# M481_v1 register map
File version: 1.0
Registers are 32-bit, read-write, reset 0x0 unless marked. A register's access mark holds for its fields unless they carry their own. Offsets are from the block's base; [hi:lo] are bit positions; {n}, {i} and the like mark numbered series; 'fields as' and 'values as' point back to an identical list.

## CRYPTO — CRYPTO Register Map
Base 0x50080000
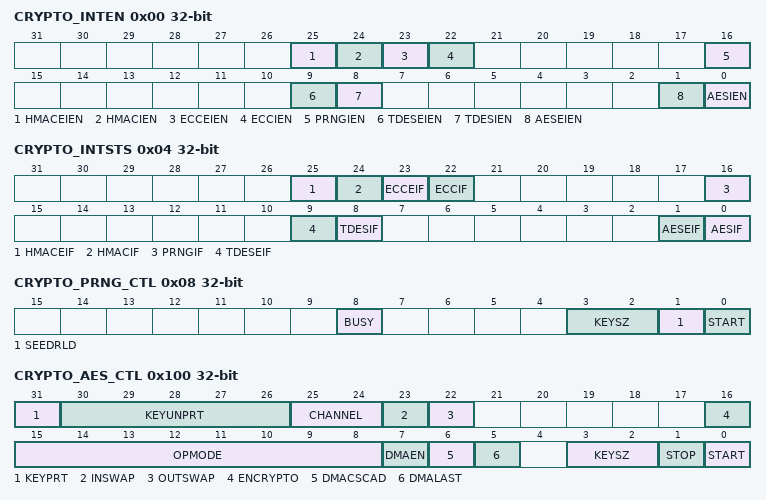
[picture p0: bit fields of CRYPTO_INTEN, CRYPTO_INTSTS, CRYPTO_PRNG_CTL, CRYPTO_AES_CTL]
0x00 CRYPTO_INTEN — Crypto Interrupt Enable Control Register
  [25] HMACEIEN — SHA/HMAC Error Interrupt Enable Bit
    0=SHA/HMAC error interrupt flag Disabled; 1=SHA/HMAC error interrupt flag Enabled
  [24] HMACIEN — SHA/HMAC Interrupt Enable Bit. Note: In DMA mode, an interrupt will be triggered when amount of data set in SHA _DMA_CNT is fed into the SHA/HMAC engine. In Non-DMA mode, an interrupt will be triggered when the SHA/HMAC engine finishes the operation.
    0=SHA/HMAC interrupt Disabled; 1=SHA/HMAC interrupt Enabled
  [23] ECCEIEN — ECC Error Interrupt Enable Bit
    0=ECC error interrupt flag Disabled; 1=ECC error interrupt flag Enabled
  [22] ECCIEN — ECC Interrupt Enable Bit. Note: In DMA mode, an interrupt will be triggered when amount of data set in ECC_DMA_CNT is fed into the ECC engine. In Non-DMA mode, an interrupt will be triggered when the ECC engine finishes the operation.
    0=ECC interrupt Disabled; 1=ECC interrupt Enabled
  [16] PRNGIEN — PRNG Interrupt Enable Bit
    0=PRNG interrupt Disabled; 1=PRNG interrupt Enabled
  [9] TDESEIEN — TDES/DES Error Flag Enable Bit
    0=TDES/DES error interrupt flag Disabled; 1=TDES/DES error interrupt flag Enabled
  [8] TDESIEN — TDES/DES Interrupt Enable Bit. Note: In DMA mode, an interrupt will be triggered when amount of data set in TDES_DMA_CNT is fed into the TDES engine. In Non-DMA mode, an interrupt will be triggered when the TDES engine finishes the operation.
    0=TDES/DES interrupt Disabled; 1=TDES/DES interrupt Enabled
  [1] AESEIEN — AES Error Flag Enable Bit
    0=AES error interrupt flag Disabled; 1=AES error interrupt flag Enabled
  [0] AESIEN — AES Interrupt Enable Bit. Note: In DMA mode, an interrupt will be triggered when amount of data set in AES_DMA_CNT is fed into the AES engine. In Non-DMA mode, an interrupt will be triggered when the AES engine finishes the operation.
    0=AES interrupt Disabled; 1=AES interrupt Enabled
0x04 CRYPTO_INTSTS — Crypto Interrupt Flag
  [25] HMACEIF — SHA/HMAC Error Flag. This register includes operating and setting error. The detail flag is shown in CRYPTO_HMAC_STS register. This bit is cleared by writing 1, and it has no effect by writing 0.
    0=No SHA/HMAC error; 1=SHA/HMAC error interrupt
  [24] HMACIF — SHA/HMAC Finish Interrupt Flag. This bit is cleared by writing 1, and it has no effect by writing 0.
    0=No SHA/HMAC interrupt; 1=SHA/HMAC operation done interrupt
  [23] ECCEIF — ECC Error Flag. This register includes operating and setting error. The detail flag is shown in CRYPTO_ECC_STS register. This bit is cleared by writing 1, and it has no effect by writing 0.
    0=No ECC error; 1=ECC error interrupt
  [22] ECCIF — ECC Finish Interrupt Flag. This bit is cleared by writing 1, and it has no effect by writing 0.
    0=No ECC interrupt; 1=ECC operation done interrupt
  [16] PRNGIF — PRNG Finish Interrupt Flag. This bit is cleared by writing 1, and it has no effect by writing 0.
    0=No PRNG interrupt; 1=PRNG key generation done interrupt
  [9] TDESEIF — TDES/DES Error Flag. This bit includes the operating and setting error. The detailed flag is shown in the CRYPTO_TDES_STS register. This includes operating and setting error. This bit is cleared by writing 1, and it has no effect by writing 0.
    0=No TDES/DES error; 1=TDES/DES encryption/decryption error interrupt
  [8] TDESIF — TDES/DES Finish Interrupt Flag. This bit is cleared by writing 1, and it has no effect by writing 0.
    0=No TDES/DES interrupt; 1=TDES/DES encryption/decryption done interrupt
  [1] AESEIF — AES Error Flag. This bit is cleared by writing 1, and it has no effect by writing 0.
    0=No AES error; 1=AES encryption/decryption error interrupt
  [0] AESIF — AES Finish Interrupt Flag. This bit is cleared by writing 1, and it has no effect by writing 0.
    0=No AES interrupt; 1=AES encryption/decryption done interrupt
0x08 CRYPTO_PRNG_CTL — PRNG Control Register
  [8] BUSY ro — PRNG Busy (Read Only)
    0=PRNG engine is idle; 1=Indicate that the PRNG engine is generating CRYPTO_PRNG_KEYx
  [3:2] KEYSZ — PRNG Generate Key Size
    0=64 bits; 1=128 bits; 2=192 bits; 3=256 bits
  [1] SEEDRLD — Reload New Seed for PRNG Engine
    0=Generating key based on the current seed; 1=Reload new seed
  [0] START — Start PRNG Engine
    0=Stop PRNG engine; 1=Generate new key and store the new key to register CRYPTO_PRNG_KEYx, which will be cleared when the new key is generated
0x0C CRYPTO_PRNG_SEED wo reset not defined — Seed for PRNG
  [31:0] SEED — Seed for PRNG (Write Only). The bits store the seed for PRNG engine.
{0x10+4i} CRYPTO_PRNG_KEY{i} ro reset not defined (i=0..7) — PRNG Generated Key{i}
  [31:0] KEY — Store PRNG Generated Key (Read Only). The bits store the key that is generated by PRNG.
{0x50+4i} CRYPTO_AES_FDBCK{i} ro (i=0..3) — AES Engine Output Feedback Data After Cryptographic Operation
  [31:0] FDBCK — AES Feedback Information. The feedback value is 128 bits in size. The AES engine uses the data from CRYPTO_AES_FDBCKx as the data inputted to CRYPTO_AESn_IVx for the next block in DMA cascade mode. The AES engine outputs feedback information for IV in the next block's operation. Software can use this feedback information to implement more than four DMA channels. Software can store that feedback value temporarily. After switching back, fill the stored feedback value to CRYPTO_AESn_IVx in the same channel operation, and then continue the operation with the original setting.
0x60 CRYPTO_TDES_FDBCKH ro — TDES/DES Engine Output Feedback High Word Data After Cryptographic Operation
  [31:0] FDBCK — TDES/DES Feedback. The feedback value is 64 bits in size. The TDES/DES engine uses the data from {CRYPTO_TDES_FDBCKH, CRYPTO_TDES_FDBCKL} as the data inputted to {CRYPTO_TDESn_IVH, CRYPTO_TDESn_IVL} for the next block in DMA cascade mode. The feedback register is for CBC, CFB, and OFB mode. TDES/DES engine outputs feedback information for IV in the next block's operation. Software can use this feedback information to implement more than four DMA channels. Software can store that feedback value temporarily. After switching back, fill the stored feedback value to CRYPTO_TDESn_IVH/L in the same channel operation. Then can continue the operation with the original setting.
0x64 CRYPTO_TDES_FDBCKL ro — TDES/DES Engine Output Feedback Low Word Data After Cryptographic Operation
  fields as CRYPTO_TDES_FDBCKH
0x100 CRYPTO_AES_CTL — AES Control Register
  [31] KEYPRT — Protect Key. Read as a flag to reflect KEYPRT.
    0=No effect; 1=Protect the content of the AES key from reading. The return value for reading CRYPTO_AESn_KEYx is not the content of the registers CRYPTO_AESn_KEYx. Once it is set, it can be cleared by asserting KEYUNPRT. And the key content would be cleared as well
  [30:26] KEYUNPRT — Unprotect Key. Writing 0 to CRYPTO_AES_CTL[31] and '10110' to CRYPTO_AES_CTL[30:26] is that AES key is unprotected. The KEYUNPRT can be read and written. When it is written as the AES engine is operating, BUSY flag is 1, there would be no effect on KEYUNPRT.
  [25:24] CHANNEL — AES Engine Working Channel
    {v}=Current control register setting is for channel {v} (v=0..3)
  [23] INSWAP — AES Engine Input Data Swap
    0=Keep the original order; 1=The order that CPU feeds data to the accelerator will be changed from {byte3, byte2, byte1, byte0} to {byte0, byte1, byte2, byte3}
  [22] OUTSWAP — AES Engine Output Data Swap
    0=Keep the original order; 1=The order that CPU outputs data from the accelerator will be changed from {byte3, byte2, byte1, byte0} to {byte0, byte1, byte2, byte3}
  [16] ENCRYPTO — AES Encryption/Decryption
    0=AES engine executes decryption operation; 1=AES engine executes encryption operation
  [15:8] OPMODE — AES Engine Operation Modes
    0=ECB (Electronic Codebook Mode) 0x01 = CBC (Cipher Block Chaining Mode); 2=CFB (Cipher Feedback Mode); 3=OFB (Output Feedback Mode); 4=CTR (Counter Mode); 16=CBC-CS1 (CBC Ciphertext-Stealing 1 Mode); 17=CBC-CS2 (CBC Ciphertext-Stealing 2 Mode); 18=CBC-CS3 (CBC Ciphertext-Stealing 3 Mode)
  [7] DMAEN — AES Engine DMA Enable Bit. The AES engine operates in DMA mode, and data movement from/to the engine is done by DMA logic.
    0=AES DMA engine Disabled; 1=AES_DMA engine Enabled
  [6] DMACSCAD — AES Engine DMA with Cascade Mode
    0=DMA cascade function Disabled; 1=In DMA cascade mode, software can update DMA source address register, destination address register, and byte count register during a cascade operation, without finishing the accelerator operation
  [5] DMALAST — AES Last Block. In DMA mode, this bit must be set as beginning the last DMA cascade round. In Non-DMA mode, this bit must be set when feeding in the last block of data in ECB, CBC, CTR, OFB, and CFB mode, and feeding in the (last-1) block of data at CBC-CS1, CBC-CS2, and CBC-CS3 mode. This bit is always 0 when it's read back. Must be written again once START is triggered.
  [3:2] KEYSZ — AES Key Size. This bit defines three different key size for AES operation. If the AES accelerator is operating and the corresponding flag BUSY is 1, updating this register has no effect.
  [1] STOP — AES Engine Stop. Note: This bit is always 0 when it's read back.
    0=No effect; 1=Stop AES engine
  [0] START — AES Engine Start. Note: This bit is always 0 when it's read back.
    0=No effect; 1=Start AES engine. BUSY flag will be set
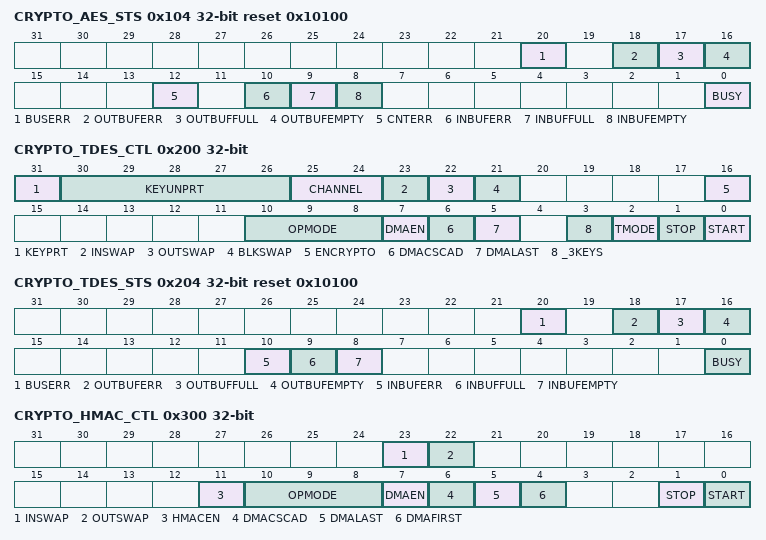
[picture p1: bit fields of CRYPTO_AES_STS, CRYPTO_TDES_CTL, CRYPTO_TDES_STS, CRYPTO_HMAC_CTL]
0x104 CRYPTO_AES_STS ro reset 0x10100 — AES Engine Flag
  [20] BUSERR — AES DMA Access Bus Error Flag
    0=No error; 1=Bus error will stop DMA operation and AES engine
  [18] OUTBUFERR — AES Out Buffer Error Flag
    0=No error; 1=Error happens during getting the result from AES engine
  [17] OUTBUFFULL — AES Out Buffer Full Flag
    0=AES output buffer is not full; 1=AES output buffer is full, and software needs to get data from CRYPTO_AES_DATOUT. Otherwise, the AES engine will be pending since the output buffer is full
  [16] OUTBUFEMPTY — AES Out Buffer Empty
    0=AES output buffer is not empty. There are some valid data kept in output buffer; 1=AES output buffer is empty. Software cannot get data from CRYPTO_AES_DATOUT. Otherwise, the flag OUTBUFERR will be set to 1 since the output buffer is empty
  [12] CNTERR — CRYPTO_AESn_CNT Setting Error
    0=No error in CRYPTO_AESn_CNT setting; 1=CRYPTO_AESn_CNT is 0 if DMAEN(CRYPTO_AES_CTL[7]) is enabled
  [10] INBUFERR — AES Input Buffer Error Flag
    0=No error; 1=Error happens during feeding data to the AES engine
  [9] INBUFFULL — AES Input Buffer Full Flag
    0=AES input buffer is not full. Software can feed the data into the AES engine; 1=AES input buffer is full. Software cannot feed data to the AES engine. Otherwise, the flag INBUFERR will be set to 1
  [8] INBUFEMPTY — AES Input Buffer Empty
    0=There are some data in input buffer waiting for the AES engine to process; 1=AES input buffer is empty. Software needs to feed data to the AES engine. Otherwise, the AES engine will be pending to wait for input data
  [0] BUSY — AES Engine Busy
    0=The AES engine is idle or finished; 1=The AES engine is under processing
0x108 CRYPTO_AES_DATIN — AES Engine Data Input Port Register
  [31:0] DATIN — AES Engine Input Port. CPU feeds data to AES engine through this port by checking CRYPTO_AES_STS. Feed data when INBUFFULL is 0.
0x10C CRYPTO_AES_DATOUT ro — AES Engine Data Output Port Register
  [31:0] DATOUT — AES Engine Output Port. CPU gets results from the AES engine through this port by checking CRYPTO_AES_STS. Get data when OUTBUFEMPTY is 0.
{0x110+4i} CRYPTO_AES0_KEY{i} (i=0..7) — AES Key Word {i} Register for Channel 0
  [31:0] KEY — CRYPTO_AESn_KEYx. The KEY keeps the security key for AES operation. {CRYPTO_AESn_KEY3, CRYPTO_AESn_KEY2, CRYPTO_AESn_KEY1, CRYPTO_AESn_KEY0} stores the 128-bit security key for AES operation. {CRYPTO_AESn_KEY5, CRYPTO_AESn_KEY4, CRYPTO_AESn_KEY3, CRYPTO_AESn_KEY2, CRYPTO_AESn_KEY1, CRYPTO_AESn_KEY0} stores the 192-bit security key for AES operation. {CRYPTO_AESn_KEY7, CRYPTO_AESn_KEY6, CRYPTO_AESn_KEY5, CRYPTO_AESn_KEY4, CRYPTO_AESn_KEY3, CRYPTO_AESn_KEY2, CRYPTO_AESn_KEY1, CRYPTO_AESn_KEY0} stores the 256-bit security key for AES operation.
{0x130+0x3C*i} CRYPTO_AES{i}_IV0 (i=0..3) — AES Initial Vector Word 0 Register for Channel {i}
  [31:0] IV — AES Initial Vectors. Four initial vectors (CRYPTO_AESn_IV0, CRYPTO_AESn_IV1, CRYPTO_AESn_IV2, and CRYPTO_AESn_IV3) are for AES operating in CBC, CFB, and OFB mode. Four registers (CRYPTO_AESn_IV0, CRYPTO_AESn_IV1, CRYPTO_AESn_IV2, and CRYPTO_AESn_IV3) act as Nonce counter when the AES engine is operating in CTR mode.
{0x134+0x3C*i} CRYPTO_AES{i}_IV1 (i=0..3) — AES Initial Vector Word 1 Register for Channel {i}
  fields as CRYPTO_AES0_IV0
{0x138+0x3C*i} CRYPTO_AES{i}_IV2 (i=0..3) — AES Initial Vector Word 2 Register for Channel {i}
  fields as CRYPTO_AES0_IV0
{0x13C+0x3C*i} CRYPTO_AES{i}_IV3 (i=0..3) — AES Initial Vector Word 3 Register for Channel {i}
  fields as CRYPTO_AES0_IV0
{0x140+0x3C*i} CRYPTO_AES{i}_SADDR (i=0..3) — AES DMA Source Address Register for Channel {i}
  [31:0] SADDR — AES DMA Source Address. The AES accelerator supports DMA function to transfer the plain text between SRAM memory space and embedded FIFO. The SADDR keeps the source address of the data buffer where the source text is stored. Based on the source address, the AES accelerator can read the plain text (encryption) / cipher text (descryption) from SRAM memory space and do AES operation. The start of source address should be located at word boundary. In other words, bit 1 and 0 of SADDR are ignored. SADDR can be read and written. Writing to SADDR while the AES accelerator is operating doesn't affect the current AES operation. But the value of SADDR will be updated later on. Consequently, software can prepare the DMA source address for the next AES operation. In DMA mode, software can update the next CRYPTO_AESn_SADDR before triggering START. The value of CRYPTO_AESn_SADDR and CRYPTO_AESn_DADDR can be the same.
{0x144+0x3C*i} CRYPTO_AES{i}_DADDR (i=0..3) — AES DMA Destination Address Register for Channel {i}
  [31:0] DADDR — AES DMA Destination Address. The AES accelerator supports DMA function to transfer the cipher text between SRAM memory space and embedded FIFO. The DADDR keeps the destination address of the data buffer where the engine output's text will be stored. Based on the destination address, the AES accelerator can write the cipher text (encryption) / plain text (decryption) back to SRAM memory space after the AES operation is finished. The start of destination address should be located at word boundary. In other words, bit 1 and 0 of DADDR are ignored. DADDR can be read and written. Writing to DADDR while the AES accelerator is operating doesn't affect the current AES operation. But the value of DADDR will be updated later on. Consequently, software can prepare the destination address for the next AES operation. In DMA mode, software can update the next CRYPTO_AESn_DADDR before triggering START. The value of CRYPTO_AESn_SADDR and CRYPTO_AESn_DADDR can be the same.
{0x148+0x3C*i} CRYPTO_AES{i}_CNT (i=0..3) — AES Byte Count Register for Channel {i}
  [31:0] CNT — AES Byte Count. The CRYPTO_AESn_CNT keeps the byte count of source text that is for the AES engine operating in DMA mode. The CRYPTO_AESn_CNT is 32-bit and the maximum of byte count is 4G bytes. CRYPTO_AESn_CNT can be read and written. Writing to CRYPTO_AESn_CNT while the AES accelerator is operating doesn't affect the current AES operation. But the value of CRYPTO_AESn_CNT will be updated later on. Consequently, software can prepare the byte count of data for the next AES operation. According to CBC-CS1, CBC-CS2, and CBC-CS3 standard, the count of operation data must be more than 16 bytes. Operations that are qual or less than one block will output unexpected result. In Non-DMA ECB, CBC, CFB, OFB, and CTR mode, CRYPTO_AESn_CNT must be set as byte count for the last block of data before feeding in the last block of data. In Non-DMA CBC-CS1, CBC-CS2, and CBC-CS3 mode, CRYPTO_AESn_CNT must be set as byte count for the last two blocks of data before feeding in the last two blocks of data.
{0x14C+4i} CRYPTO_AES1_KEY{i} (i=0..7) — AES Key Word {i} Register for Channel 1
  fields as CRYPTO_AES0_KEY0
{0x188+4i} CRYPTO_AES2_KEY{i} (i=0..7) — AES Key Word {i} Register for Channel 2
  fields as CRYPTO_AES0_KEY0
{0x1C4+4i} CRYPTO_AES3_KEY{i} (i=0..7) — AES Key Word {i} Register for Channel 3
  fields as CRYPTO_AES0_KEY0
0x200 CRYPTO_TDES_CTL — TDES/DES Control Register
  [31] KEYPRT — Protect Key. Read as a flag to reflect KEYPRT.
    0=No effect; 1=This bit is to protect the content of TDES key from reading. The return value for reading CRYPTO_ TDESn_KEYxH/L is not the content in the registers CRYPTO_ TDESn_KEYxH/L. Once it is set, it can be cleared by asserting KEYUNPRT. The key content would be cleared as well
  [30:26] KEYUNPRT — Unprotect Key. Writing 0 to CRYPTO_TDES_CTL [31] and '10110' to CRYPTO_TDES_CTL [30:26] is that TDES key is unprotected. The KEYUNPRT can be read and written. When it is written as the TDES engine is operating, BUSY flag is 1, there would be no effect on KEYUNPRT.
  [25:24] CHANNEL — TDES/DES Engine Working Channel
    values as CRYPTO_AES_CTL.CHANNEL
  [23] INSWAP — TDES/DES Engine Input Data Swap
    values as CRYPTO_AES_CTL.INSWAP
  [22] OUTSWAP — TDES/DES Engine Output Data Swap
    values as CRYPTO_AES_CTL.OUTSWAP
  [21] BLKSWAP — TDES/DES Engine Block Double Word Endian Swap
    0=Keep the original order, e.g. {WORD_H, WORD_L}; 1=When this bit is set to 1, the TDES engine would exchange high and low word in the sequence {WORD_L, WORD_H}
  [16] ENCRYPTO — TDES/DES Encryption/Decryption
    0=TDES engine executes decryption operation; 1=TDES engine executes encryption operation
  [10:8] OPMODE — TDES/DES Engine Operation Mode
    0=ECB (Electronic Codebook Mode); 1=CBC (Cipher Block Chaining Mode); 2=CFB (Cipher Feedback Mode); 3=OFB (Output Feedback Mode); 4=CTR (Counter Mode)
  [7] DMAEN — TDES/DES Engine DMA Enable Bit. TDES engine operates in DMA mode, and data movement from/to the engine is done by DMA logic.
    0=TDES_DMA engine Disabled; 1=TDES_DMA engine Enabled
  [6] DMACSCAD — TDES/DES Engine DMA with Cascade Mode
    0=DMA cascade function Disabled; 1=In DMA Cascade mode, software can update DMA source address register, destination address register, and byte count register during a cascade operation, without finishing the accelerator operation
  [5] DMALAST — TDES/DES Engine Start for the Last Block. In DMA mode, this bit must be set as beginning the last DMA cascade round. In Non-DMA mode, this bit must be set as feeding in last block of data.
  [3] _3KEYS — TDES/DES Key Number
    0=Select KEY1 and KEY2 in TDES/DES engine; 1=Triple keys in TDES/DES engine Enabled
  [2] TMODE — TDES/DES Engine Operating Mode
    0=Set DES mode for TDES/DES engine; 1=Set Triple DES mode for TDES/DES engine
  [1] STOP — TDES/DES Engine Stop. Note: The bit is always 0 when it's read back.
    0=No effect; 1=Stop TDES/DES engine
  [0] START — TDES/DES Engine Start. Note: The bit is always 0 when it's read back.
    0=No effect; 1=Start TDES/DES engine. The flag BUSY would be set
0x204 CRYPTO_TDES_STS ro reset 0x10100 — TDES/DES Engine Flag
  [20] BUSERR — TDES/DES DMA Access Bus Error Flag
    0=No error; 1=Bus error will stop DMA operation and TDES/DES engine
  [18] OUTBUFERR — TDES/DES Out Buffer Error Flag
    0=No error; 1=Error happens during getting test result from TDES/DES engine
  [17] OUTBUFFULL — TDES/DES Output Buffer Full Flag
    0=TDES/DES output buffer is not full; 1=TDES/DES output buffer is full, and software needs to get data from TDES_DATA_OUT. Otherwise, the TDES/DES engine will be pending since output buffer is full
  [16] OUTBUFEMPTY — TDES/DES Output Buffer Empty Flag
    0=TDES/DES output buffer is not empty. There are some valid data kept in output buffer; 1=TDES/DES output buffer is empty, Software cannot get data from TDES_DATA_OUT. Otherwise the flag OUTBUFERR will be set to 1, since output buffer is empty
  [10] INBUFERR — TDES/DES in Buffer Error Flag
    0=No error; 1=Error happens during feeding data to the TDES/DES engine
  [9] INBUFFULL — TDES/DES in Buffer Full Flag
    0=TDES/DES input buffer is not full. Software can feed the data into the TDES/DES engine; 1=TDES input buffer is full. Software cannot feed data to the TDES/DES engine. Otherwise, the flag INBUFERR will be set to 1
  [8] INBUFEMPTY — TDES/DES in Buffer Empty
    0=There are some data in input buffer waiting for the TDES/DES engine to process; 1=TDES/DES input buffer is empty. Software needs to feed data to the TDES/DES engine. Otherwise, the TDES/DES engine will be pending to wait for input data
  [0] BUSY — TDES/DES Engine Busy
    0=TDES/DES engine is idle or finished; 1=TDES/DES engine is under processing
{0x208+0x40*i} CRYPTO_TDES{i}_KEY1H (i=0..3) — TDES/DES Key 1 High Word Register for Channel {i}
  [31:0] KEY — TDES/DES Key High/Low Word. The key registers for TDES/DES algorithm calculation. The security key for the TDES/DES accelerator is 64 bits. Thus, it needs two 32-bit registers to store a security key. The register CRYPTO_TDESn_KEYxH is used to keep the bit [63:32] of security key for the TDES/DES operation, while the register CRYPTO_TDESn_KEYxL is used to keep the bit [31:0].
{0x20C+0x40*i} CRYPTO_TDES{i}_KEY1L (i=0..3) — TDES/DES Key 1 Low Word Register for Channel {i}
  fields as CRYPTO_TDES0_KEY1H
{0x210+0x40*i} CRYPTO_TDES{i}_KEY2H (i=0..3) — TDES Key 2 High Word Register for Channel {i}
  fields as CRYPTO_TDES0_KEY1H
{0x214+0x40*i} CRYPTO_TDES{i}_KEY2L (i=0..3) — TDES Key 2 Low Word Register for Channel {i}
  fields as CRYPTO_TDES0_KEY1H
{0x218+0x40*i} CRYPTO_TDES{i}_KEY3H (i=0..3) — TDES Key 3 High Word Register for Channel {i}
  fields as CRYPTO_TDES0_KEY1H
{0x21C+0x40*i} CRYPTO_TDES{i}_KEY3L (i=0..3) — TDES Key 3 Low Word Register for Channel {i}
  fields as CRYPTO_TDES0_KEY1H
{0x220+0x40*i} CRYPTO_TDES{i}_IVH (i=0..3) — TDES/DES Initial Vector High Word Register for Channel {i}
  [31:0] IV — TDES/DES Initial Vector High/Low Word. Initial vector (IV) is for TDES/DES engine in CBC, CFB, and OFB mode. IV is Nonce counter for TDES/DES engine in CTR mode.
{0x224+0x40*i} CRYPTO_TDES{i}_IVL (i=0..3) — TDES/DES Initial Vector Low Word Register for Channel {i}
  fields as CRYPTO_TDES0_IVH
{0x228+0x40*i} CRYPTO_TDES{i}_SADDR (i=0..3) — TDES/DES DMA Source Address Register for Channel {i}
  [31:0] SADDR — TDES/DES DMA Source Address. The TDES/DES accelerator supports DMA function to transfer the plain text between SRAM memory space and embedded FIFO. The CRYPTO_TDESn_SADDR keeps the source address of the data buffer where the source text is stored. Based on the source address, the TDES/DES accelerator can read the plain text (encryption) / cipher text (decryption) from SRAM memory space and do TDES/DES operation. The start of source address should be located at word boundary. In other words, bit 1 and 0 of CRYPTO_TDESn_SADDR are ignored. CRYPTO_TDESn_SADDR can be read and written. Writing to CRYPTO_TDESn_SADDR while the TDES/DES accelerator is operating doesn't affect the current TDES/DES operation. But the value of CRYPTO_TDESn_SADDR will be updated later on. Consequently, software can prepare the DMA source address for the next TDES/DES operation. In DMA mode, software can update the next CRYPTO_TDESn_SADDR before triggering START. CRYPTO_TDESn_SADDR and CRYPTO_TDESn_DADDR can be the same in the value.
{0x22C+0x40*i} CRYPTO_TDES{i}_DADDR (i=0..3) — TDES/DES DMA Destination Address Register for Channel {i}
  [31:0] DADDR — TDES/DES DMA Destination Address. The TDES/DES accelerator supports DMA function to transfer the cipher text between SRAM memory space and embedded FIFO. The CRYPTO_TDESn_DADDR keeps the destination address of the data buffer where the engine output's text will be stored. Based on the destination address, the TDES/DES accelerator can write the cipher text (encryption) / plain text (decryption) back to SRAM memory space after the TDES/DES operation is finished. The start of destination address should be located at word boundary. In other words, bit 1 and 0 of CRYPTO_TDESn_DADDR are ignored. CRYPTO_TDESn_DADDR can be read and written. Writing to CRYPTO_TDESn_DADDR while the TDES/DES accelerator is operating doesn't affect the current TDES/DES operation. But the value of CRYPTO_TDESn_DADDR will be updated later on. Consequently, software can prepare the destination address for the next TDES/DES operation. In DMA mode, software can update the next CRYPTO_TDESn_DADDR before triggering START. CRYPTO_TDESn_SADDR and CRYPTO_TDESn_DADDR can be the same in the value.
{0x230+0x40*i} CRYPTO_TDES{i}_CNT (i=0..3) — TDES/DES Byte Count Register for Channel {i}
  [31:0] CNT — TDES/DES Byte Count. The CRYPTO_TDESn_CNT keeps the byte count of source text that is for the TDES/DES engine operating in DMA mode. The CRYPTO_TDESn_CNT is 32-bit and the maximum of byte count is 4G bytes. CRYPTO_TDESn_CNT can be read and written. Writing to CRYPTO_TDESn_CNT while the TDES/DES accelerator is operating doesn't affect the current TDES/DES operation. But the value of CRYPTO_TDESn_CNT will be updated later on. Consequently, software can prepare the byte count of data for the next TDES /DES operation. In Non-DMA ECB, CBC, CFB, OFB, and CTR mode, CRYPTO_TDESn_CNT must be set as byte count for the last block of data before feeding in the last block of data.
0x234 CRYPTO_TDES_DATIN — TDES/DES Engine Input Data Word Register
  [31:0] DATIN — TDES/DES Engine Input Port. CPU feeds data to TDES/DES engine through this port by checking CRYPTO_TDES_STS. Feed data when INBUFFULL is 0.
0x238 CRYPTO_TDES_DATOUT ro — TDES/DES Engine Output Data Word Register
  [31:0] DATOUT — TDES/DES Engine Output Port. CPU gets result from the TDES/DES engine through this port by checking CRYPTO_TDES_STS. Get data when OUTBUFEMPTY is 0.
0x300 CRYPTO_HMAC_CTL — SHA/HMAC Control Register
  [23] INSWAP — SHA/HMAC Engine Input Data Swap
    values as CRYPTO_AES_CTL.INSWAP
  [22] OUTSWAP — SHA/HMAC Engine Output Data Swap
    values as CRYPTO_AES_CTL.INSWAP
  [11] HMACEN — HMAC_SHA Engine Operating Mode
    0=Execute SHA function; 1=Execute HMAC function
  [10:8] OPMODE — SHA/HMAC Engine Operation Modes. 0x0xx: SHA160. 0x100: SHA256. 0x101: SHA224. 0x110: SHA512. 0x111: SHA384. Note: These bits can be read and written. But writing to them wouldn't take effect as BUSY is 1.
  [7] DMAEN — SHA/HMAC Engine DMA Enable Bit. SHA/HMAC engine operates in DMA mode, and data movement from/to the engine is done by DMA logic.
    0=SHA/HMAC DMA engine Disabled; 1=SHA/HMAC DMA engine Enabled
  [6] DMACSCAD — SHA/HMAC Engine DMA with Cascade Mode
    values as CRYPTO_AES_CTL.DMACSCAD
  [5] DMALAST — SHA/HMAC Last Block. This bit must be set as feeding in last byte of data.
  [4] DMAFIRST — SHA/HMAC First Block in Cascadefunction. This bit must be set as feeding in first byte of data.
  [1] STOP — SHA/HMAC Engine Stop. Note: This bit is always 0 when it's read back.
    0=No effect; 1=Stop SHA/HMAC engine
  [0] START — SHA/HMAC Engine Start. Note: This bit is always 0 when it's read back.
    0=No effect; 1=Start SHA/HMAC engine. BUSY flag will be set
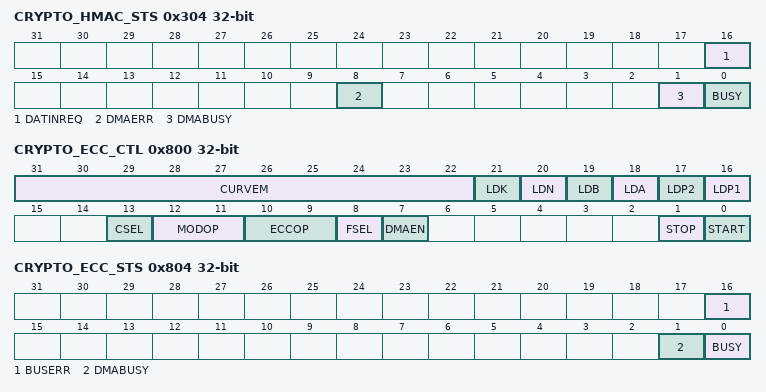
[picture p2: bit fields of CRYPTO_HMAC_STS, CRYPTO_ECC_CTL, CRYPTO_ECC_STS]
0x304 CRYPTO_HMAC_STS ro — SHA/HMAC Status Flag
  [16] DATINREQ — SHA/HMAC Non-dMA Mode Data Input Request
    0=No effect; 1=Request SHA/HMAC Non-DMA mode data input
  [8] DMAERR — SHA/HMAC Engine DMA Error Flag
    0=Show the SHA/HMAC engine access normal; 1=Show the SHA/HMAC engine access error
  [1] DMABUSY — SHA/HMAC Engine DMA Busy Flag
    0=SHA/HMAC DMA engine is idle or finished; 1=SHA/HMAC DMA engine is busy
  [0] BUSY — SHA/HMAC Engine Busy
    0=SHA/HMAC engine is idle or finished; 1=SHA/HMAC engine is busy
{0x308+4i} CRYPTO_HMAC_DGST{i} ro (i=0..15) — SHA/HMAC Digest Message {i}
  [31:0] DGST — SHA/HMAC Digest Message Output Register. For SHA-160, the digest is stored in CRYPTO_HMAC_DGST0 ~ CRYPTO_HMAC_DGST4. For SHA-224, the digest is stored in CRYPTO_HMAC_DGST0 ~ CRYPTO_HMAC_DGST6. For SHA-256, the digest is stored in CRYPTO_HMAC_DGST0 ~ CRYPTO_HMAC_DGST7. For SHA-384, the digest is stored in CRYPTO_HMAC_DGST0 ~ CRYPTO_HMAC_DGST11. For SHA-512, the digest is stored in CRYPTO_HMAC_DGST0 ~ CRYPTO_HMAC_DGST15.
0x348 CRYPTO_HMAC_KEYCNT — SHA/HMAC Key Byte Count Register
  [31:0] KEYCNT — SHA/HMAC Key Byte Count. The CRYPTO_HMAC_KEYCNT keeps the byte count of key that SHA/HMAC engine operates. The register is 32-bit and the maximum byte count is 4G bytes. It can be read and written. Writing to the register CRYPTO_HMAC_KEYCNT as the SHA/HMAC accelerator operating doesn't affect the current SHA/HMAC operation. But the value of CRYPTO_SHA _KEYCNT will be updated later on. Consequently, software can prepare the key count for the next SHA/HMAC operation.
0x34C CRYPTO_HMAC_SADDR — SHA/HMAC DMA Source Address Register
  [31:0] SADDR — SHA/HMAC DMA Source Address. The SHA/HMAC accelerator supports DMA function to transfer the plain text between SRAM memory space and embedded FIFO. The CRYPTO_HMAC_SADDR keeps the source address of the data buffer where the source text is stored. Based on the source address, the SHA/HMAC accelerator can read the plain text from SRAM memory space and do SHA/HMAC operation. The start of source address should be located at word boundary. In other words, bit 1 and 0 of CRYPTO_HMAC_SADDR are ignored. CRYPTO_HMAC_SADDR can be read and written. Writing to CRYPTO_HMAC_SADDR while the SHA/HMAC accelerator is operating doesn't affect the current SHA/HMAC operation. But the value of CRYPTO_HMAC_SADDR will be updated later on. Consequently, software can prepare the DMA source address for the next SHA/HMAC operation. In DMA mode, software can update the next CRYPTO_HMAC_SADDR before triggering START. CRYPTO_HMAC_SADDR and CRYPTO_HMAC_DADDR can be the same in the value.
0x350 CRYPTO_HMAC_DMACNT — SHA/HMAC Byte Count Register
  [31:0] DMACNT — SHA/HMAC Operation Byte Count. The CRYPTO_HMAC_DMACNT keeps the byte count of source text that is for the SHA/HMAC engine operating in DMA mode. The CRYPTO_HMAC_DMACNT is 32-bit and the maximum of byte count is 4G bytes. CRYPTO_HMAC_DMACNT can be read and written. Writing to CRYPTO_HMAC_DMACNT while the SHA/HMAC accelerator is operating doesn't affect the current SHA/HMAC operation. But the value of CRYPTO_HMAC_DMACNT will be updated later on. Consequently, software can prepare the byte count of data for the next SHA/HMAC operation. In Non-DMA mode, CRYPTO_HMAC_DMACNT must be set as the byte count of the last block before feeding in the last block of data.
0x354 CRYPTO_HMAC_DATIN — SHA/HMAC Engine Non-dMA Mode Data Input Port Register
  [31:0] DATIN — SHA/HMAC Engine Input Port. CPU feeds data to SHA/HMAC engine through this port by checking CRYPTO_HMAC_STS. Feed data when DATINREQ is 1.
0x800 CRYPTO_ECC_CTL — ECC Control Register
  [31:22] CURVEM — The key length of elliptic curve.
  [21] LDK — The Control Signal of Register for SCALARK
    0=The register for SCALARK is not modified by DMA or user; 1=The register for SCALARK is modified by DMA or user
  [20] LDN — The Control Signal of Register for the Parameter CURVEN of Elliptic Curve
    0=The register for CURVEN is not modified by DMA or user; 1=The register for CURVEN is modified by DMA or user
  [19] LDB — The Control Signal of Register for the Parameter CURVEB of Elliptic Curve
    0=The register for CURVEB is not modified by DMA or user; 1=The register for CURVEB is modified by DMA or user
  [18] LDA — The Control Signal of Register for the Parameter CURVEA of Elliptic Curve
    0=The register for CURVEA is not modified by DMA or user; 1=The register for CURVEA is modified by DMA or user
  [17] LDP2 — The Control Signal of Register for the x and Y Coordinate of the Second Point (POINTX2, POINTY2)
    0=The register for POINTX2 and POINTY2 is not modified by DMA or user; 1=The register for POINTX2 and POINTY2 is modified by DMA or user
  [16] LDP1 — The Control Signal of Register for the x and Y Coordinate of the First Point (POINTX1, POINTY1)
    0=The register for POINTX1 and POINTY1 is not modified by DMA or user; 1=The register for POINTX1 and POINTY1 is modified by DMA or user
  [13] CSEL — Curve Selection
    0=NIST suggested curve; 1=Montgomery curve
  [12:11] MODOP — Modulus Operation for PF
    0=Division :; 1=Multiplication :; 2=Addition :; 3=Subtraction :
  [10:9] ECCOP — Point Operation for BF and PF. Besides above three input data, point operations still need the parameters of elliptic curve (CURVEA, CURVEB, CURVEN and CURVEM) as shown in Figure 6.27-11.
    0=Point multiplication :; 1=Modulus operation : choose by MODOP (CRYPTO_ECC_CTL[12:11]); 2=Point addition :; 3=Point doubling :
  [8] FSEL — Field Selection
    0=Binary Field (GF(2m )); 1=Prime Field (GF(p))
  [7] DMAEN — ECC Accelerator DMA Enable Bit. Only when START and DMAEN are 1, ECC DMA engine will be active
    0=ECC DMA engine Disabled; 1=ECC DMA engine Enabled
  [1] STOP — ECC Accelerator Stop. This bit is always 0 when it's read back. Remember to clear ECC interrupt flag after stopping ECC accelerator.
    0=No effect; 1=Abort ECC accelerator and make it into idle state
  [0] START — ECC Accelerator Start. This bit is always 0 when it's read back. ECC accelerator will ignore this START signal when BUSY flag is 1.
    0=No effect; 1=Start ECC accelerator. BUSY flag will be set
0x804 CRYPTO_ECC_STS ro — ECC Status Register
  [16] BUSERR — ECC DMA Access Bus Error Flag
    0=No error; 1=Bus error will stop DMA operation and ECC accelerator
  [1] DMABUSY — ECC DMA Busy Flag
    0=ECC DMA is idle or finished; 1=ECC DMA is busy
  [0] BUSY — ECC Accelerator Busy Flag. Remember to clear ECC interrupt flag after ECC accelerator finished
    0=The ECC accelerator is idle or finished; 1=The ECC accelerator is under processing and protects all registers
{0x808+4i} CRYPTO_ECC_X1_{i:02} (i=0..17) — ECC X-coordinate Word{i} of the First Point
  [31:0] POINTX1 — ECC the X-coordinate Value of the First Point (POINTX1). For B-163 or K-163, POINTX1 is stored in CRYPTO_ECC_X1_00~CRYPTO_ECC_X1_05. For B-233 or K-233, POINTX1 is stored in CRYPTO_ECC_X1_00~CRYPTO_ECC_X1_07. For B-283 or K-283, POINTX1 is stored in CRYPTO_ECC_X1_00~CRYPTO_ECC_X1_08. For B-409 or K-409, POINTX1 is stored in CRYPTO_ECC_X1_00~CRYPTO_ECC_X1_12. For B-571 or K-571, POINTX1 is stored in CRYPTO_ECC_X1_00~CRYPTO_ECC_X1_17. For P-192, POINTX1 is stored in CRYPTO_ECC_X1_00~CRYPTO_ECC_X1_05. For P-224, POINTX1 is stored in CRYPTO_ECC_X1_00~CRYPTO_ECC_X1_06. For P-256, POINTX1 is stored in CRYPTO_ECC_X1_00~CRYPTO_ECC_X1_07. For P-384, POINTX1 is stored in CRYPTO_ECC_X1_00~CRYPTO_ECC_X1_11. For P-521, POINTX1 is stored in CRYPTO_ECC_X1_00~CRYPTO_ECC_X1_16
{0x850+4i} CRYPTO_ECC_Y1_{i:02} (i=0..17) — ECC Y-coordinate Word{i} of the First Point
  [31:0] POINTY1 — ECC the Y-coordinate Value of the First Point (POINTY1). For B-163 or K-163, POINTY1 is stored in CRYPTO_ECC_Y1_00~CRYPTO_ECC_Y1_05. For B-233 or K-233, POINTY1 is stored in CRYPTO_ECC_Y1_00~CRYPTO_ECC_Y1_07. For B-283 or K-283, POINTY1 is stored in CRYPTO_ECC_Y1_00~CRYPTO_ECC_Y1_08. For B-409 or K-409, POINTY1 is stored in CRYPTO_ECC_Y1_00~CRYPTO_ECC_Y1_12. For B-571 or K-571, POINTY1 is stored in CRYPTO_ECC_Y1_00~CRYPTO_ECC_Y1_17. For P-192, POINTY1 is stored in CRYPTO_ECC_Y1_00~CRYPTO_ECC_Y1_05. For P-224, POINTY1 is stored in CRYPTO_ECC_Y1_00~CRYPTO_ECC_Y1_06. For P-256, POINTY1 is stored in CRYPTO_ECC_Y1_00~CRYPTO_ECC_Y1_07. For P-384, POINTY1 is stored in CRYPTO_ECC_Y1_00~CRYPTO_ECC_Y1_11. For P-521, POINTY1 is stored in CRYPTO_ECC_Y1_00~CRYPTO_ECC_Y1_16
{0x898+4i} CRYPTO_ECC_X2_{i:02} (i=0..17) — ECC X-coordinate Word{i} of the Second Point
  [31:0] POINTX2 — ECC the X-coordinate Value of the Second Point (POINTX2). For B-163 or K-163, POINTX2 is stored in CRYPTO_ECC_X2_00~CRYPTO_ECC_X2_05. For B-233 or K-233, POINTX2 is stored in CRYPTO_ECC_X2_00~CRYPTO_ECC_X2_07. For B-283 or K-283, POINTX2 is stored in CRYPTO_ECC_X2_00~CRYPTO_ECC_X2_08. For B-409 or K-409, POINTX2 is stored in CRYPTO_ECC_X2_00~CRYPTO_ECC_X2_12. For B-571 or K-571, POINTX2 is stored in CRYPTO_ECC_X2_00~CRYPTO_ECC_X2_17. For P-192, POINTX2 is stored in CRYPTO_ECC_X2_00~CRYPTO_ECC_X2_05. For P-224, POINTX2 is stored in CRYPTO_ECC_X2_00~CRYPTO_ECC_X2_06. For P-256, POINTX2 is stored in CRYPTO_ECC_X2_00~CRYPTO_ECC_X2_07. For P-384, POINTX2 is stored in CRYPTO_ECC_X2_00~CRYPTO_ECC_X2_11. For P-521, POINTX2 is stored in CRYPTO_ECC_X2_00~CRYPTO_ECC_X2_16
{0x8E0+4i} CRYPTO_ECC_Y2_{i:02} (i=0..17) — ECC Y-coordinate Word{i} of the Second Point
  [31:0] POINTY2 — ECC the Y-coordinate Value of the Second Point (POINTY2). For B-163 or K-163, POINTY2 is stored in CRYPTO_ECC_Y2_00~CRYPTO_ECC_Y2_05. For B-233 or K-233, POINTY2 is stored in CRYPTO_ECC_Y2_00~CRYPTO_ECC_Y2_07. For B-283 or K-283, POINTY2 is stored in CRYPTO_ECC_Y2_00~CRYPTO_ECC_Y2_08. For B-409 or K-409, POINTY2 is stored in CRYPTO_ECC_Y2_00~CRYPTO_ECC_Y2_12. For B-571 or K-571, POINTY2 is stored in CRYPTO_ECC_Y2_00~CRYPTO_ECC_Y2_17. For P-192, POINTY2 is stored in CRYPTO_ECC_Y2_00~CRYPTO_ECC_Y2_05. For P-224, POINTY2 is stored in CRYPTO_ECC_Y2_00~CRYPTO_ECC_Y2_06. For P-256, POINTY2 is stored in CRYPTO_ECC_Y2_00~CRYPTO_ECC_Y2_07. For P-384, POINTY2 is stored in CRYPTO_ECC_Y2_00~CRYPTO_ECC_Y2_11. For P-521, POINTY2 is stored in CRYPTO_ECC_Y2_00~CRYPTO_ECC_Y2_16
{0x928+4i} CRYPTO_ECC_A_{i:02} (i=0..17) — ECC Parameter CURVEA Word{i} of Elliptic Curve
  [31:0] CURVEA — ECC the Parameter CURVEA Value of Elliptic Curve (CURVEA). For B-163 or K-163, CURVEA is stored in CRYPTO_ECC_A_00~CRYPTO_ECC_A_05. For B-233 or K-233, CURVEA is stored in CRYPTO_ECC_A_00~CRYPTO_ECC_A_07. For B-283 or K-283, CURVEA is stored in CRYPTO_ECC_A_00~CRYPTO_ECC_A_08. For B-409 or K-409, CURVEA is stored in CRYPTO_ECC_A_00~CRYPTO_ECC_A_12. For B-571 or K-571, CURVEA is stored in CRYPTO_ECC_A_00~CRYPTO_ECC_A_17. For P-192, CURVEA is stored in CRYPTO_ECC_A_00~CRYPTO_ECC_A_05. For P-224, CURVEA is stored in CRYPTO_ECC_A_00~CRYPTO_ECC_A_06. For P-256, CURVEA is stored in CRYPTO_ECC_A_00~CRYPTO_ECC_A_07. For P-384, CURVEA is stored in CRYPTO_ECC_A_00~CRYPTO_ECC_A_11. For P-521, CURVEA is stored in CRYPTO_ECC_A_00~CRYPTO_ECC_A_16
{0x970+4i} CRYPTO_ECC_B_{i:02} (i=0..17) — ECC Parameter CURVEB Word{i} of Elliptic Curve
  [31:0] CURVEB — ECC the Parameter CURVEB Value of Elliptic Curve (CURVEA). For B-163 or K-163, CURVEB is stored in CRYPTO_ECC_B_00~CRYPTO_ECC_B_05. For B-233 or K-233, CURVEB is stored in CRYPTO_ECC_B_00~CRYPTO_ECC_B_07. For B-283 or K-283, CURVEB is stored in CRYPTO_ECC_B_00~CRYPTO_ECC_B_08. For B-409 or K-409, CURVEB is stored in CRYPTO_ECC_B_00~CRYPTO_ECC_B_12. For B-521 or K-521, CURVEB is stored in CRYPTO_ECC_B_00~CRYPTO_ECC_B_17. For P-192, CURVEB is stored in CRYPTO_ECC_B_00~CRYPTO_ECC_B_05. For P-224, CURVEB is stored in CRYPTO_ECC_B_00~CRYPTO_ECC_B_06. For P-256, CURVEB is stored in CRYPTO_ECC_B_00~CRYPTO_ECC_B_07. For P-384, CURVEB is stored in CRYPTO_ECC_B_00~CRYPTO_ECC_B_11. For P-521, CURVEB is stored in CRYPTO_ECC_B_00~CRYPTO_ECC_B_16
{0x9B8+4i} CRYPTO_ECC_N_{i:02} (i=0..17) — ECC Parameter CURVEN Word{i} of Elliptic Curve
  [31:0] CURVEN — ECC the Parameter CURVEN Value of Elliptic Curve (CURVEN). In GF(p), CURVEN is the prime p. In GF(2m), CURVEN is the irreducible polynomial. For B-163 or K-163, CURVEN is stored in CRYPTO_ECC_N_00~CRYPTO_ECC_N_05. For B-233 or K-233, CURVEN is stored in CRYPTO_ECC_N_00~CRYPTO_ECC_N_07. For B-283 or K-283, CURVEN is stored in CRYPTO_ECC_N_00~CRYPTO_ECC_N_08. For B-409 or K-409, CURVEN is stored in CRYPTO_ECC_N_00~CRYPTO_ECC_N_12. For B-571 or K-571, CURVEN is stored in CRYPTO_ECC_N_00~CRYPTO_ECC_N_17. For P-192, CURVEN is stored in CRYPTO_ECC_N_00~CRYPTO_ECC_N_05. For P-224, CURVEN is stored in CRYPTO_ECC_N_00~CRYPTO_ECC_N_06. For P-256, CURVEN is stored in CRYPTO_ECC_N_00~CRYPTO_ECC_N_07. For P-384, CURVEN is stored in CRYPTO_ECC_N_00~CRYPTO_ECC_N_11. For P-521, CURVEN is stored in CRYPTO_ECC_N_00~CRYPTO_ECC_N_16
{0xA00+4i} CRYPTO_ECC_K_{i:02} wo (i=0..17) — ECC Scalar SCALARK Word{i} of Point Multiplication
  [31:0] SCALARK — ECC the Scalar SCALARK Value of Point Multiplication(SCALARK). Because the SCALARK usually stores the private key, ECC accelerator do not allow to read the register SCALARK. For B-163 or K-163, SCALARK is stored in CRYPTO_ECC_K_00~CRYPTO_ECC_K_05. For B-233 or K-233, SCALARK is stored in CRYPTO_ECC_K_00~CRYPTO_ECC_K_07. For B-283 or K-283, SCALARK is stored in CRYPTO_ECC_K_00~CRYPTO_ECC_K_08. For B-409 or K-409, SCALARK is stored in CRYPTO_ECC_K_00~CRYPTO_ECC_K_12. For B-571 or K-571, SCALARK is stored in CRYPTO_ECC_K_00~CRYPTO_ECC_K_17. For P-192, SCALARK is stored in CRYPTO_ECC_K_00~CRYPTO_ECC_K_05. For P-224, SCALARK is stored in CRYPTO_ECC_K_00~CRYPTO_ECC_K_06. For P-256, SCALARK is stored in CRYPTO_ECC_K_00~CRYPTO_ECC_K_07. For P-384, SCALARK is stored in CRYPTO_ECC_K_00~CRYPTO_ECC_K_11. For P-521, SCALARK is stored in CRYPTO_ECC_K_00~CRYPTO_ECC_K_16
0xA48 CRYPTO_ECC_SADDR — ECC DMA Source Address Register
0xA4C CRYPTO_ECC_DADDR — ECC DMA Destination Address Register
  [31:0] DADDR — ECC DMA Destination Address. The ECC accelerator supports DMA function to transfer the DATA and PARAMETER between SRAM memory and ECC accelerator. The DADDR keeps the destination address of the data buffer where output data of ECC engine will be stored. Based on the destination address, the ECC accelerator can write the result data back to SRAM memory space after the ECC operation is finished. The start of destination address should be located at word boundary. That is, bit 1 and 0 of DADDR are ignored. DADDR can be read and written. In DMA mode, software must update the CRYPTO_ECC_DADDR before triggering START.
0xA50 CRYPTO_ECC_STARTREG — ECC Starting Address of Updated Registers
  [31:0] STARTREG — ECC Starting Address of Updated Registers. The address of the updated registers that DMA feeds the first data or parameter to ECC engine. When ECC engine is active, ECC accelerator does not allow users to modify STARTREG, for example, to update input data from register CRYPTO_ECC POINTX1. Thus, the value of STARTREG is 0x808.
0xA54 CRYPTO_ECC_WORDCNT — ECC DMA Word Count
  [31:0] WORDCNT — ECC DMA Word Count. The CRYPTO_ECC_WORDCNT keeps the word count of source data that is for the required input data of ECC accelerator with various operations in DMA mode. Although CRYPTO_ECC_WORDCNT is 32-bit, the maximum of word count in ECC accelerator is 144 words. CRYPTO_ECC_WORDCNT can be read and written.
